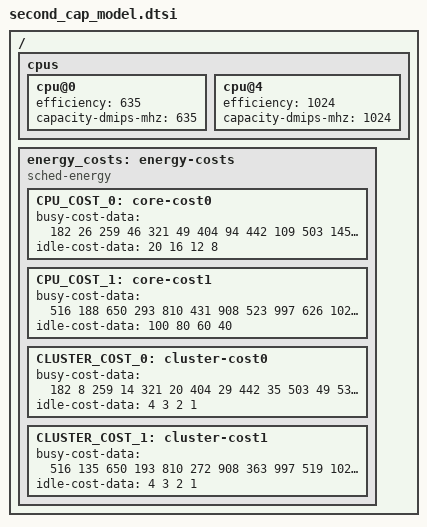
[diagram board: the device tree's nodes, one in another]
/*
 * Auto-generated legacy EAS energy model for incorporation in SoC device tree.
 * Generated by freqbench postprocessing scripts using freqbench results.
 * More info at https://github.com/kdrag0n/freqbench
 */

/ {
	cpus {
		cpu@0 {
			efficiency = <635>;
			capacity-dmips-mhz = <635>;
		};

		cpu@4 {
			efficiency = <1024>;
			capacity-dmips-mhz = <1024>;
		};
	};

	energy_costs: energy-costs {
		compatible = "sched-energy";

		CPU_COST_0: core-cost0 {
			busy-cost-data = <
				  182   26
				  259   46
				  321   49
				  404   94
				  442  109
				  503  145
				  531  176
			>;
			idle-cost-data = <
				20 16 12 8
			>;
		};

		CPU_COST_1: core-cost1 {
			busy-cost-data = <
				  516  188
				  650  293
				  810  431
				  908  523
				  997  626
				 1024  733
			>;
			idle-cost-data = <
				100 80 60 40
			>;
		};

		CLUSTER_COST_0: cluster-cost0 {
			busy-cost-data = <
				  182    8
				  259   14
				  321   20
				  404   29
				  442   35
				  503   49
				  531   62
			>;
			idle-cost-data = <
				4 3 2 1
			>;
		};

		CLUSTER_COST_1: cluster-cost1 {
			busy-cost-data = <
				  516  135
				  650  193
				  810  272
				  908  363
				  997  519
				 1024  585
			>;
			idle-cost-data = <
				4 3 2 1
			>;
		};
	};
};
